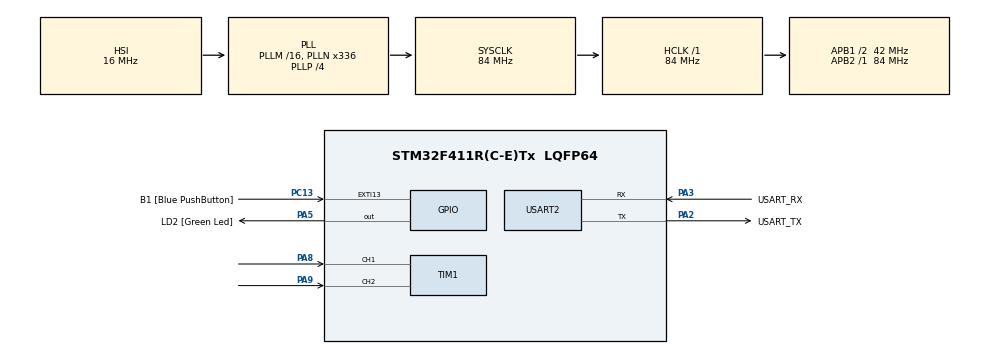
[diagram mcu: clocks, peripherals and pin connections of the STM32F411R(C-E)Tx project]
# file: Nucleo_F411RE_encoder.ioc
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Mcu.Family=STM32F4
PC15-OSC32_OUT.Mode=LSE-External-Oscillator
RCC.CortexFreq_Value=84000000
PC13-ANTI_TAMP.GPIO_Label=B1 [Blue PushButton]
PA14.GPIO_Label=TCK
PH1\ -\ OSC_OUT.Mode=HSE-External-Clock-Source
TIM1.EncoderMode=TIM_ENCODERMODE_TI12
RCC.APB1CLKDivider=RCC_HCLK_DIV2
PC14-OSC32_IN.Signal=RCC_OSC32_IN
RCC.SYSCLKSource=RCC_SYSCLKSOURCE_PLLCLK
ProjectManager.StackSize=0x400
PA13.Signal=SYS_JTMS-SWDIO
PA3.Mode=Asynchronous
TIM1.AutoReloadPreload=TIM_AUTORELOAD_PRELOAD_ENABLE
PH0\ -\ OSC_IN.Mode=HSE-External-Clock-Source
SH.S_TIM1_CH1.0=TIM1_CH1,Encoder_Interface
PH0\ -\ OSC_IN.Signal=RCC_OSC_IN
ProjectManager.TargetToolchain=STM32CubeIDE
RCC.HCLKFreq_Value=84000000
RCC.APB2TimFreq_Value=84000000
PA9.Signal=S_TIM1_CH2
PC15-OSC32_OUT.Signal=RCC_OSC32_OUT
RCC.AHBFreq_Value=84000000
PA5.Signal=GPIO_Output
RCC.HSE_VALUE=8000000
PH1\ -\ OSC_OUT.Signal=RCC_OSC_OUT
board=NUCLEO-F411RE
PC13-ANTI_TAMP.Signal=GPXTI13
RCC.VCOOutputFreq_Value=336000000
RCC.APB2Freq_Value=84000000
PC14-OSC32_IN.Mode=LSE-External-Oscillator
SH.S_TIM1_CH2.0=TIM1_CH2,Encoder_Interface
PA14.Mode=Serial_Wire
PA8.Signal=S_TIM1_CH1
PA13.Mode=Serial_Wire
Mcu.Name=STM32F411R(C-E)Tx
PA2.Signal=USART2_TX
PA13.GPIO_Label=TMS
RCC.FLatency-AdvancedSettings=FLASH_LATENCY_2
RCC.48MHZClocksFreq_Value=84000000
PB3.Signal=SYS_JTDO-SWO
RCC.SYSCLKFreq_VALUE=84000000
Mcu.Package=LQFP64
PA5.GPIO_Label=LD2 [Green Led]
USART2.VirtualMode=VM_ASYNC
PC13-ANTI_TAMP.GPIO_ModeDefaultEXTI=GPIO_MODE_IT_FALLING
PA2.GPIO_Label=USART_TX
PA14.Signal=SYS_JTCK-SWCLK
ProjectManager.HeapSize=0x200
RCC.HSI_VALUE=16000000
RCC.PLLP=RCC_PLLP_DIV4
NVIC.PriorityGroup=NVIC_PRIORITYGROUP_0
RCC.PLLN=336
RCC.APB1TimFreq_Value=84000000
PA2.Mode=Asynchronous
RCC.APB1Freq_Value=42000000
PA3.GPIO_Label=USART_RX
PA3.Signal=USART2_RX
PB3.GPIO_Label=SWO

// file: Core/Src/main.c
/* USER CODE BEGIN Header */

//https://deepbluembedded.com/stm32-timer-encoder-mode-stm32-rotary-encoder-interfacing/
//
//PA8     ------> TIM1_CH1
//PA9     ------> TIM1_CH2
//In stm32f4xx_hal_msp.c change GPIO_NOPULL to GPIO_PULLUP
//GPIO_InitStruct.Pull = GPIO_PULLUP;

/**
  ******************************************************************************
  * @file           : main.c
  * @brief          : Main program body
  ******************************************************************************
  * @attention
  *
  * <h2><center>&copy; Copyright (c) 2020 STMicroelectronics.
  * All rights reserved.</center></h2>
  *
  * This software component is licensed by ST under BSD 3-Clause license,
  * the "License"; You may not use this file except in compliance with the
  * License. You may obtain a copy of the License at:
  *                        opensource.org/licenses/BSD-3-Clause
  *
  ******************************************************************************
  */
/* USER CODE END Header */
#include "main.h"

/* USER CODE BEGIN Includes */

#include <stdio.h>
#include <stdlib.h>
#include <string.h>

/* USER CODE END Includes */

TIM_HandleTypeDef htim1;

UART_HandleTypeDef huart2;

void SystemClock_Config(void);
static void MX_GPIO_Init(void);
static void MX_USART2_UART_Init(void);
static void MX_TIM1_Init(void);

/* USER CODE BEGIN 0 */

// WARNING UART6 is connected to st-link
int _write(int file, char *ptr, int len)
{
	HAL_UART_Transmit(&huart2,(uint8_t *)ptr,len,10);
	return len;
}

/*
int _write(int file, char *ptr, int len)
{
	for (uint8_t i=0; i<len; i++){
		LL_USART_TransmitData8(USART2, ptr[i]);
		while ( !LL_USART_IsActiveFlag_TXE(USART2) )
		{
		}
	}
	return len;
}
 */

int UART_Transmit(USART_TypeDef *UART, uint8_t *ptr, int len){
	for (uint8_t i=0; i<len; i++){
		LL_USART_TransmitData8(UART, ptr[i]);
		while ( !LL_USART_IsActiveFlag_TXE(UART) )
		{
		}
	}
	return 0;
}

/* USER CODE END 0 */

int main(void)
{

  /* MCU Configuration--------------------------------------------------------*/

  /* Reset of all peripherals, Initializes the Flash interface and the Systick. */
  HAL_Init();

  /* Configure the system clock */
  SystemClock_Config();

  /* Initialize all configured peripherals */
  MX_GPIO_Init();
  MX_USART2_UART_Init();
  MX_TIM1_Init();
  /* USER CODE BEGIN 2 */

  HAL_TIM_Encoder_Start(&htim1, TIM_CHANNEL_ALL);

  /* USER CODE END 2 */

  /* Infinite loop */
  while (1)
  {

    /* USER CODE BEGIN 3 */
	  printf("%u \n", __HAL_TIM_GET_COUNTER(&htim1));
	  //HAL_Delay(500);
  }
  /* USER CODE END 3 */
}

void SystemClock_Config(void)
{
  RCC_OscInitTypeDef RCC_OscInitStruct = {0};
  RCC_ClkInitTypeDef RCC_ClkInitStruct = {0};

  /** Configure the main internal regulator output voltage
  */
  __HAL_RCC_PWR_CLK_ENABLE();
  __HAL_PWR_VOLTAGESCALING_CONFIG(PWR_REGULATOR_VOLTAGE_SCALE1);
  /** Initializes the RCC Oscillators according to the specified parameters
  * in the RCC_OscInitTypeDef structure.
  */
  RCC_OscInitStruct.OscillatorType = RCC_OSCILLATORTYPE_HSI;
  RCC_OscInitStruct.HSIState = RCC_HSI_ON;
  RCC_OscInitStruct.HSICalibrationValue = RCC_HSICALIBRATION_DEFAULT;
  RCC_OscInitStruct.PLL.PLLState = RCC_PLL_ON;
  RCC_OscInitStruct.PLL.PLLSource = RCC_PLLSOURCE_HSI;
  RCC_OscInitStruct.PLL.PLLM = 16;
  RCC_OscInitStruct.PLL.PLLN = 336;
  RCC_OscInitStruct.PLL.PLLP = RCC_PLLP_DIV4;
  RCC_OscInitStruct.PLL.PLLQ = 4;
  if (HAL_RCC_OscConfig(&RCC_OscInitStruct) != HAL_OK)
  {
    Error_Handler();
  }
  /** Initializes the CPU, AHB and APB buses clocks
  */
  RCC_ClkInitStruct.ClockType = RCC_CLOCKTYPE_HCLK|RCC_CLOCKTYPE_SYSCLK
                              |RCC_CLOCKTYPE_PCLK1|RCC_CLOCKTYPE_PCLK2;
  RCC_ClkInitStruct.SYSCLKSource = RCC_SYSCLKSOURCE_PLLCLK;
  RCC_ClkInitStruct.AHBCLKDivider = RCC_SYSCLK_DIV1;
  RCC_ClkInitStruct.APB1CLKDivider = RCC_HCLK_DIV2;
  RCC_ClkInitStruct.APB2CLKDivider = RCC_HCLK_DIV1;

  if (HAL_RCC_ClockConfig(&RCC_ClkInitStruct, FLASH_LATENCY_2) != HAL_OK)
  {
    Error_Handler();
  }
}

static void MX_TIM1_Init(void)
{

  TIM_Encoder_InitTypeDef sConfig = {0};
  TIM_MasterConfigTypeDef sMasterConfig = {0};

  htim1.Instance = TIM1;
  htim1.Init.Prescaler = 0;
  htim1.Init.CounterMode = TIM_COUNTERMODE_UP;
  htim1.Init.Period = 65535;
  htim1.Init.ClockDivision = TIM_CLOCKDIVISION_DIV1;
  htim1.Init.RepetitionCounter = 0;
  htim1.Init.AutoReloadPreload = TIM_AUTORELOAD_PRELOAD_ENABLE;
  sConfig.EncoderMode = TIM_ENCODERMODE_TI12;
  sConfig.IC1Polarity = TIM_ICPOLARITY_RISING;
  sConfig.IC1Selection = TIM_ICSELECTION_DIRECTTI;
  sConfig.IC1Prescaler = TIM_ICPSC_DIV1;
  sConfig.IC1Filter = 0;
  sConfig.IC2Polarity = TIM_ICPOLARITY_RISING;
  sConfig.IC2Selection = TIM_ICSELECTION_DIRECTTI;
  sConfig.IC2Prescaler = TIM_ICPSC_DIV1;
  sConfig.IC2Filter = 0;
  if (HAL_TIM_Encoder_Init(&htim1, &sConfig) != HAL_OK)
  {
    Error_Handler();
  }
  sMasterConfig.MasterOutputTrigger = TIM_TRGO_RESET;
  sMasterConfig.MasterSlaveMode = TIM_MASTERSLAVEMODE_DISABLE;
  if (HAL_TIMEx_MasterConfigSynchronization(&htim1, &sMasterConfig) != HAL_OK)
  {
    Error_Handler();
  }

}

static void MX_USART2_UART_Init(void)
{

  huart2.Instance = USART2;
  huart2.Init.BaudRate = 115200;
  huart2.Init.WordLength = UART_WORDLENGTH_8B;
  huart2.Init.StopBits = UART_STOPBITS_1;
  huart2.Init.Parity = UART_PARITY_NONE;
  huart2.Init.Mode = UART_MODE_TX_RX;
  huart2.Init.HwFlowCtl = UART_HWCONTROL_NONE;
  huart2.Init.OverSampling = UART_OVERSAMPLING_16;
  if (HAL_UART_Init(&huart2) != HAL_OK)
  {
    Error_Handler();
  }

}

static void MX_GPIO_Init(void)
{
  GPIO_InitTypeDef GPIO_InitStruct = {0};

  /* GPIO Ports Clock Enable */
  __HAL_RCC_GPIOC_CLK_ENABLE();
  __HAL_RCC_GPIOH_CLK_ENABLE();
  __HAL_RCC_GPIOA_CLK_ENABLE();
  __HAL_RCC_GPIOB_CLK_ENABLE();

  /*Configure GPIO pin Output Level */
  HAL_GPIO_WritePin(LD2_GPIO_Port, LD2_Pin, GPIO_PIN_RESET);

  /*Configure GPIO pin : B1_Pin */
  GPIO_InitStruct.Pin = B1_Pin;
  GPIO_InitStruct.Mode = GPIO_MODE_IT_FALLING;
  GPIO_InitStruct.Pull = GPIO_NOPULL;
  HAL_GPIO_Init(B1_GPIO_Port, &GPIO_InitStruct);

  /*Configure GPIO pin : LD2_Pin */
  GPIO_InitStruct.Pin = LD2_Pin;
  GPIO_InitStruct.Mode = GPIO_MODE_OUTPUT_PP;
  GPIO_InitStruct.Pull = GPIO_NOPULL;
  GPIO_InitStruct.Speed = GPIO_SPEED_FREQ_LOW;
  HAL_GPIO_Init(LD2_GPIO_Port, &GPIO_InitStruct);

}

void Error_Handler(void)
{
}

/************************ (C) COPYRIGHT STMicroelectronics *****END OF FILE****/
